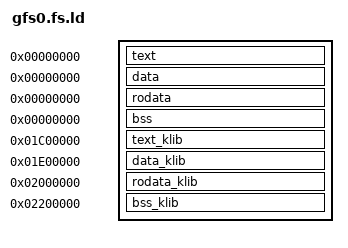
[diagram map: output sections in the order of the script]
/* 
 * File Generated by GEOS buildExec 
 * Copyright (c) 2023 DefinitelyNotAGirl@github 
 */
OUTPUT_FORMAT("elf64-x86-64")
ENTRY(init)
SECTIONS {
	. = 0x0000000000000000;
	text : {
		build/gfs0.fs/*.o (.text*)
	}
	. = 0x0000000000000000;
	data : {
		build/gfs0.fs/*.o (.data*)
	}
	. = 0x0000000000000000;
	rodata : {
		build/gfs0.fs/*.o (.rodata*)
	}
	. = 0x0000000000000000;
	bss : {
		build/gfs0.fs/*.o (.bss*)
	}
	. = 0x1C00000;
	text_klib : {
		build/klib/*.o (.text*)
	}
	. = 0x1E00000;
	data_klib : {
		build/klib/*.o (.data*)
	}
	. = 0x2000000;
	rodata_klib : {
		build/klib/*.o (.rodata*)
	}
	. = 0x2200000;
	bss_klib : {
		build/klib/*.o (.bss*)
	}
	/DISCARD/ : {
		*(.note*)
		*(.iplt*)
		*(.igot*)
		*(.rel*)
		*(.comment*)
		*(.eh_frame*)
	}
}
